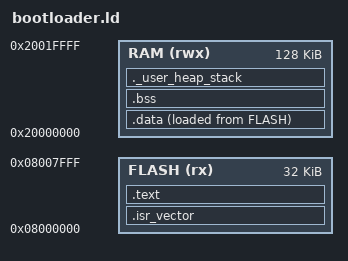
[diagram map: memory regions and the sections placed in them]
/* Linker script for the OTA bootloader.
 * Confines it to sectors 0-1 (32 KB) starting at the true flash base.
 * This is a normal, complete linker script -- the bootloader is a
 * standalone binary, not linked against anything else. */

ENTRY(Reset_Handler)

MEMORY
{
  FLASH (rx)  : ORIGIN = 0x08000000, LENGTH = 32K
  RAM   (rwx) : ORIGIN = 0x20000000, LENGTH = 128K  /* adjust to your part's SRAM size */
}

_estack = ORIGIN(RAM) + LENGTH(RAM);

SECTIONS
{
  .isr_vector :
  {
    . = ALIGN(4);
    KEEP(*(.isr_vector))
    . = ALIGN(4);
  } > FLASH

  .text :
  {
    . = ALIGN(4);
    *(.text)
    *(.text*)
    *(.rodata)
    *(.rodata*)
    . = ALIGN(4);
    _etext = .;
  } > FLASH

  .data :
  {
    . = ALIGN(4);
    _sdata = .;
    *(.data)
    *(.data*)
    . = ALIGN(4);
    _edata = .;
  } > RAM AT> FLASH
  _sidata = LOADADDR(.data);

  .bss :
  {
    . = ALIGN(4);
    _sbss = .;
    *(.bss)
    *(.bss*)
    *(COMMON)
    . = ALIGN(4);
    _ebss = .;
  } > RAM

  ._user_heap_stack :
  {
    . = ALIGN(8);
    PROVIDE ( end = . );
    . = . + 0x400;    /* minimum heap -- bootloader barely needs any */
    . = ALIGN(8);
  } > RAM

  /DISCARD/ :
  {
    libc.a ( * )
    libm.a ( * )
    libgcc.a ( * )
  }
}
